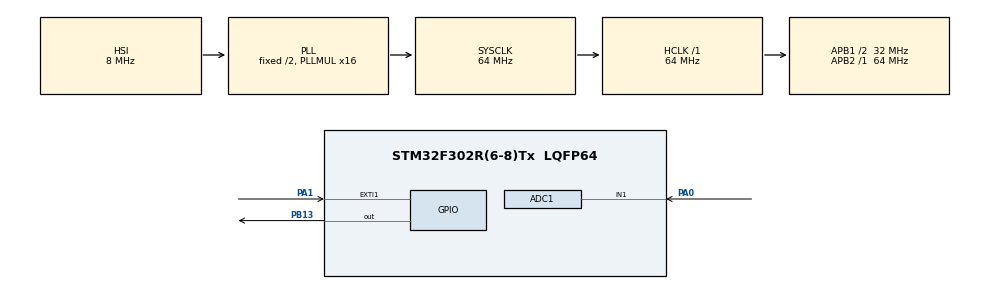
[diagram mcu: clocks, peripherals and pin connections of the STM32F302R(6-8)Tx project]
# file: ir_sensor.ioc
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ADC1.Channel-0\#ChannelRegularConversion=ADC_CHANNEL_1
ADC1.ContinuousConvMode=ENABLE
ADC1.NbrOfConversionFlag=1
ADC1.Offset-0\#ChannelRegularConversion=0
ADC1.OffsetNumber-0\#ChannelRegularConversion=ADC_OFFSET_NONE
ADC1.Rank-0\#ChannelRegularConversion=1
ADC1.SamplingTime-0\#ChannelRegularConversion=ADC_SAMPLETIME_601CYCLES_5
ADC1.SamplingTimeOPAMP-0\#ChannelRegularConversion=ADC_SAMPLETIME_61CYCLES_5
ADC1.SubFamily=STM32F302x8
ADC1.master=1
Mcu.Family=STM32F3
Mcu.Name=STM32F302R(6-8)Tx
Mcu.Package=LQFP64
NVIC.ADC1_IRQn=true\:0\:0\:false\:false\:true\:true\:true\:true
NVIC.EXTI1_IRQn=true\:0\:0\:false\:false\:true\:true\:true\:true
NVIC.PriorityGroup=NVIC_PRIORITYGROUP_0
PA0.Mode=IN1-Single-Ended
PA0.Signal=ADC1_IN1
PA1.Signal=GPXTI1
PA13.Mode=Serial_Wire
PA13.Signal=SYS_JTMS-SWDIO
PA14.Mode=Serial_Wire
PA14.Signal=SYS_JTCK-SWCLK
PB13.Signal=GPIO_Output
PF0-OSC_IN.Mode=HSE-External-Oscillator
PF0-OSC_IN.Signal=RCC_OSC_IN
PF1-OSC_OUT.Mode=HSE-External-Oscillator
PF1-OSC_OUT.Signal=RCC_OSC_OUT
ProjectManager.HeapSize=0x200
ProjectManager.StackSize=0x400
ProjectManager.TargetToolchain=STM32CubeIDE
RCC.AHBFreq_Value=64000000
RCC.APB1CLKDivider=RCC_HCLK_DIV2
RCC.APB1Freq_Value=32000000
RCC.APB1TimFreq_Value=64000000
RCC.APB2Freq_Value=64000000
RCC.APB2TimFreq_Value=64000000
RCC.CortexFreq_Value=64000000
RCC.HCLKFreq_Value=64000000
RCC.HSE_VALUE=8000000
RCC.HSI_VALUE=8000000
RCC.LSE_VALUE=32768
RCC.PLLM=8
RCC.PLLMUL=RCC_PLL_MUL16
RCC.PLLN=336
RCC.PLLP=RCC_PLLP_DIV4
RCC.PLLQ=7
RCC.RCC_PLLsource_Clock_Source_FROM_HSE=RCC_HSE_PREDIV_DIV2
RCC.SYSCLKFreq_VALUE=64000000
RCC.SYSCLKSourceVirtual=RCC_SYSCLKSOURCE_PLLCLK
RCC.USBFreq_Value=64000000
board=NUCLEO-F302R8

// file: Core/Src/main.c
/* USER CODE BEGIN Header */
/**
  ******************************************************************************
  * @file           : main.c
  * @brief          : Main program body
  ******************************************************************************
  * @attention
  *
  * Copyright (c) 2024 STMicroelectronics.
  * All rights reserved.
  *
  * This software is licensed under terms that can be found in the LICENSE file
  * in the root directory of this software component.
  * If no LICENSE file comes with this software, it is provided AS-IS.
  *
  ******************************************************************************
  */
/* USER CODE END Header */
#include "main.h"

ADC_HandleTypeDef hadc1;

void SystemClock_Config(void);
static void MX_GPIO_Init(void);
static void MX_ADC1_Init(void);

/* USER CODE BEGIN 0 */
uint16_t value=0;
uint32_t time=0;

void HAL_GPIO_EXTI_Callback(uint16_t GPIO_Pin)
{
value=HAL_GPIO_ReadPin(GPIOA, GPIO_PIN_1);
}
/* USER CODE END 0 */

int main(void)
{

  /* MCU Configuration--------------------------------------------------------*/

  /* Reset of all peripherals, Initializes the Flash interface and the Systick. */
  HAL_Init();

  /* Configure the system clock */
  SystemClock_Config();

  /* Initialize all configured peripherals */
  MX_GPIO_Init();
  MX_ADC1_Init();

  /* Infinite loop */
  /* USER CODE BEGIN WHILE */
  while (1)
  {
	  if(HAL_GetTick()-time>200)
	  {
		  time=HAL_GetTick();
		  HAL_GPIO_TogglePin(GPIOB, GPIO_PIN_13);
	  }
    /* USER CODE END WHILE */

  }
}

void SystemClock_Config(void)
{
  RCC_OscInitTypeDef RCC_OscInitStruct = {0};
  RCC_ClkInitTypeDef RCC_ClkInitStruct = {0};
  RCC_PeriphCLKInitTypeDef PeriphClkInit = {0};

  /** Initializes the RCC Oscillators according to the specified parameters
  * in the RCC_OscInitTypeDef structure.
  */
  RCC_OscInitStruct.OscillatorType = RCC_OSCILLATORTYPE_HSI;
  RCC_OscInitStruct.HSIState = RCC_HSI_ON;
  RCC_OscInitStruct.HSICalibrationValue = RCC_HSICALIBRATION_DEFAULT;
  RCC_OscInitStruct.PLL.PLLState = RCC_PLL_ON;
  RCC_OscInitStruct.PLL.PLLSource = RCC_PLLSOURCE_HSI;
  RCC_OscInitStruct.PLL.PLLMUL = RCC_PLL_MUL16;
  if (HAL_RCC_OscConfig(&RCC_OscInitStruct) != HAL_OK)
  {
    Error_Handler();
  }

  /** Initializes the CPU, AHB and APB buses clocks
  */
  RCC_ClkInitStruct.ClockType = RCC_CLOCKTYPE_HCLK|RCC_CLOCKTYPE_SYSCLK
                              |RCC_CLOCKTYPE_PCLK1|RCC_CLOCKTYPE_PCLK2;
  RCC_ClkInitStruct.SYSCLKSource = RCC_SYSCLKSOURCE_PLLCLK;
  RCC_ClkInitStruct.AHBCLKDivider = RCC_SYSCLK_DIV1;
  RCC_ClkInitStruct.APB1CLKDivider = RCC_HCLK_DIV2;
  RCC_ClkInitStruct.APB2CLKDivider = RCC_HCLK_DIV1;

  if (HAL_RCC_ClockConfig(&RCC_ClkInitStruct, FLASH_LATENCY_2) != HAL_OK)
  {
    Error_Handler();
  }
  PeriphClkInit.PeriphClockSelection = RCC_PERIPHCLK_ADC1;
  PeriphClkInit.Adc1ClockSelection = RCC_ADC1PLLCLK_DIV1;

  if (HAL_RCCEx_PeriphCLKConfig(&PeriphClkInit) != HAL_OK)
  {
    Error_Handler();
  }
}

static void MX_ADC1_Init(void)
{

  ADC_ChannelConfTypeDef sConfig = {0};

  /** Common config
  */
  hadc1.Instance = ADC1;
  hadc1.Init.ClockPrescaler = ADC_CLOCK_ASYNC_DIV1;
  hadc1.Init.Resolution = ADC_RESOLUTION_12B;
  hadc1.Init.ScanConvMode = ADC_SCAN_DISABLE;
  hadc1.Init.ContinuousConvMode = ENABLE;
  hadc1.Init.DiscontinuousConvMode = DISABLE;
  hadc1.Init.ExternalTrigConvEdge = ADC_EXTERNALTRIGCONVEDGE_NONE;
  hadc1.Init.ExternalTrigConv = ADC_SOFTWARE_START;
  hadc1.Init.DataAlign = ADC_DATAALIGN_RIGHT;
  hadc1.Init.NbrOfConversion = 1;
  hadc1.Init.DMAContinuousRequests = DISABLE;
  hadc1.Init.EOCSelection = ADC_EOC_SINGLE_CONV;
  hadc1.Init.LowPowerAutoWait = DISABLE;
  hadc1.Init.Overrun = ADC_OVR_DATA_OVERWRITTEN;
  if (HAL_ADC_Init(&hadc1) != HAL_OK)
  {
    Error_Handler();
  }

  /** Configure Regular Channel
  */
  sConfig.Channel = ADC_CHANNEL_1;
  sConfig.Rank = ADC_REGULAR_RANK_1;
  sConfig.SingleDiff = ADC_SINGLE_ENDED;
  sConfig.SamplingTime = ADC_SAMPLETIME_601CYCLES_5;
  sConfig.OffsetNumber = ADC_OFFSET_NONE;
  sConfig.Offset = 0;
  if (HAL_ADC_ConfigChannel(&hadc1, &sConfig) != HAL_OK)
  {
    Error_Handler();
  }

}

static void MX_GPIO_Init(void)
{
  GPIO_InitTypeDef GPIO_InitStruct = {0};

  /* GPIO Ports Clock Enable */
  __HAL_RCC_GPIOF_CLK_ENABLE();
  __HAL_RCC_GPIOA_CLK_ENABLE();
  __HAL_RCC_GPIOB_CLK_ENABLE();

  /*Configure GPIO pin Output Level */
  HAL_GPIO_WritePin(GPIOB, GPIO_PIN_13, GPIO_PIN_RESET);

  /*Configure GPIO pin : PA1 */
  GPIO_InitStruct.Pin = GPIO_PIN_1;
  GPIO_InitStruct.Mode = GPIO_MODE_IT_RISING;
  GPIO_InitStruct.Pull = GPIO_NOPULL;
  HAL_GPIO_Init(GPIOA, &GPIO_InitStruct);

  /*Configure GPIO pin : PB13 */
  GPIO_InitStruct.Pin = GPIO_PIN_13;
  GPIO_InitStruct.Mode = GPIO_MODE_OUTPUT_PP;
  GPIO_InitStruct.Pull = GPIO_NOPULL;
  GPIO_InitStruct.Speed = GPIO_SPEED_FREQ_LOW;
  HAL_GPIO_Init(GPIOB, &GPIO_InitStruct);

  /* EXTI interrupt init*/
  HAL_NVIC_SetPriority(EXTI1_IRQn, 0, 0);
  HAL_NVIC_EnableIRQ(EXTI1_IRQn);

}

void Error_Handler(void)
{
  __disable_irq();
  while (1)
  {
  }
}
